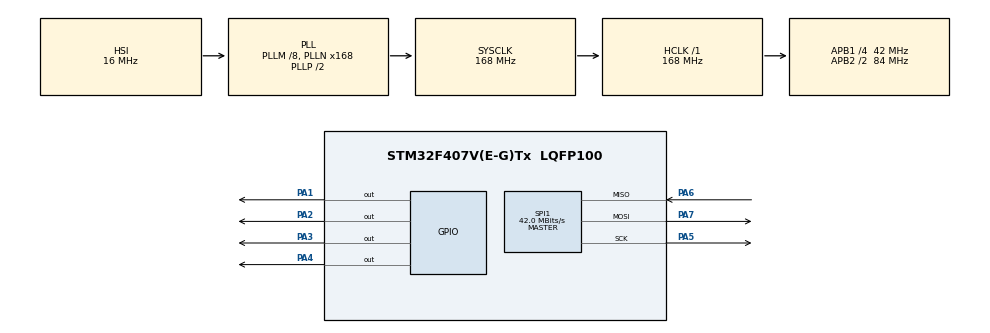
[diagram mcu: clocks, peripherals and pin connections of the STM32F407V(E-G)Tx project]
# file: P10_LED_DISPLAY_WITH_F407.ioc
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Mcu.Family=STM32F4
Mcu.Name=STM32F407V(E-G)Tx
Mcu.Package=LQFP100
NVIC.PriorityGroup=NVIC_PRIORITYGROUP_0
PA1.Signal=GPIO_Output
PA2.Signal=GPIO_Output
PA3.Signal=GPIO_Output
PA4.Signal=GPIO_Output
PA5.Mode=Full_Duplex_Master
PA5.Signal=SPI1_SCK
PA6.Mode=Full_Duplex_Master
PA6.Signal=SPI1_MISO
PA7.Mode=Full_Duplex_Master
PA7.Signal=SPI1_MOSI
ProjectManager.HeapSize=0x200
ProjectManager.StackSize=0x400
ProjectManager.TargetToolchain=STM32CubeIDE
RCC.48MHZClocksFreq_Value=48000000
RCC.AHBFreq_Value=168000000
RCC.APB1CLKDivider=RCC_HCLK_DIV4
RCC.APB1Freq_Value=42000000
RCC.APB1TimFreq_Value=84000000
RCC.APB2CLKDivider=RCC_HCLK_DIV2
RCC.APB2Freq_Value=84000000
RCC.APB2TimFreq_Value=168000000
RCC.CortexFreq_Value=168000000
RCC.HCLKFreq_Value=168000000
RCC.HSE_VALUE=8000000
RCC.HSI_VALUE=16000000
RCC.LSE_VALUE=32768
RCC.PLLM=8
RCC.PLLN=168
RCC.PLLQ=7
RCC.SYSCLKFreq_VALUE=168000000
RCC.SYSCLKSource=RCC_SYSCLKSOURCE_PLLCLK
RCC.VCOOutputFreq_Value=336000000
SPI1.CalculateBaudRate=42.0 MBits/s
SPI1.Direction=SPI_DIRECTION_2LINES
SPI1.Mode=SPI_MODE_MASTER
SPI1.VirtualType=VM_MASTER
TIM2.Period=10000
TIM2.Prescaler=8400
VP_TIM2_VS_ClockSourceINT.Mode=Internal
board=STM32F407G-DISC1

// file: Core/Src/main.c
/* USER CODE BEGIN Header */
/**
  ******************************************************************************
  * @file           : main.c
  * @brief          : Main program body
  ******************************************************************************
  * @attention
  *
  * Copyright (c) 2023 STMicroelectronics.
  * All rights reserved.
  *
  * This software is licensed under terms that can be found in the LICENSE file
  * in the root directory of this software component.
  * If no LICENSE file comes with this software, it is provided AS-IS.
  *
  ******************************************************************************
  */
/* USER CODE END Header */
#include "main.h"
#include"DMD.h"
#include"Arial14.h"
#include "Arial_Black_16_ISO_8859_1.h"
#include "Arial_black_16.h"
#include "SystemFont5x7.h"

SPI_HandleTypeDef hspi1;

TIM_HandleTypeDef htim2;

void SystemClock_Config(void);
static void MX_GPIO_Init(void);
static void MX_SPI1_Init(void);
static void MX_TIM2_Init(void);
/* USER CODE BEGIN PFP */
void DMD_scanDisplayBySPI(DMD *dmd);
/* USER CODE END PFP */

DMD *dmd;
/*** @brief  The application entry point.
  * @retval int
  */
int main(void)
{

  /* MCU Configuration--------------------------------------------------------*/

  /* Reset of all peripherals, Initializes the Flash interface and the Systick. */
  HAL_Init();

  /* Configure the system clock */
  SystemClock_Config();

  /* Initialize all configured peripherals */
  MX_GPIO_Init();
  MX_SPI1_Init();
  MX_TIM2_Init();
  /* USER CODE BEGIN 2 */
//dmd.=(1,1);

DMD_init(dmd,1,1);
  // Initialize the DMD display
//  DMD_begin(dmd);

  // Set the font for the DMD instance (replace MyFont with your font)
  DMD_selectFont(dmd,Arial_Black_16_ISO_8859_1);

  // Define the position (X, Y) where you want to draw the string
  int bX = 0;
  int bY = 0;

  // Define the string you want to display
  const char *bChars = "AAAA";

  // Get the length of the string
  uint8_t length = strlen(bChars);

  // Set the graphics mode (GRAPHICS_NORMAL, GRAPHICS_INVERSE, etc.)
  uint8_t bGraphicsMode = GRAPHICS_NORMAL;
  HAL_TIM_Base_Start_IT(&htim2);
  /* Infinite loop */
  while (1)
  {

	      // Call DMD_drawString to draw the string on the DMD display
	      DMD_drawString(dmd, bX, bY, bChars, length, bGraphicsMode);

	      // You may need to update the display and add a delay to keep the message visible

	      // Delay for 1 second to display the message
	      // You can adjust the delay duration as needed
	      HAL_Delay(1000);
	  	DMD_scanDisplayBySPI(dmd);

	      // Don't forget to free the DMD instance when done

	      return 0; /* USER CODE END 2 */

  }
}

void SystemClock_Config(void)
{
  RCC_OscInitTypeDef RCC_OscInitStruct = {0};
  RCC_ClkInitTypeDef RCC_ClkInitStruct = {0};

  /** Configure the main internal regulator output voltage
  */
  __HAL_RCC_PWR_CLK_ENABLE();
  __HAL_PWR_VOLTAGESCALING_CONFIG(PWR_REGULATOR_VOLTAGE_SCALE1);

  /** Initializes the RCC Oscillators according to the specified parameters
  * in the RCC_OscInitTypeDef structure.
  */
  RCC_OscInitStruct.OscillatorType = RCC_OSCILLATORTYPE_HSI;
  RCC_OscInitStruct.HSIState = RCC_HSI_ON;
  RCC_OscInitStruct.HSICalibrationValue = RCC_HSICALIBRATION_DEFAULT;
  RCC_OscInitStruct.PLL.PLLState = RCC_PLL_ON;
  RCC_OscInitStruct.PLL.PLLSource = RCC_PLLSOURCE_HSI;
  RCC_OscInitStruct.PLL.PLLM = 8;
  RCC_OscInitStruct.PLL.PLLN = 168;
  RCC_OscInitStruct.PLL.PLLP = RCC_PLLP_DIV2;
  RCC_OscInitStruct.PLL.PLLQ = 7;
  if (HAL_RCC_OscConfig(&RCC_OscInitStruct) != HAL_OK)
  {
    Error_Handler();
  }

  /** Initializes the CPU, AHB and APB buses clocks
  */
  RCC_ClkInitStruct.ClockType = RCC_CLOCKTYPE_HCLK|RCC_CLOCKTYPE_SYSCLK
                              |RCC_CLOCKTYPE_PCLK1|RCC_CLOCKTYPE_PCLK2;
  RCC_ClkInitStruct.SYSCLKSource = RCC_SYSCLKSOURCE_PLLCLK;
  RCC_ClkInitStruct.AHBCLKDivider = RCC_SYSCLK_DIV1;
  RCC_ClkInitStruct.APB1CLKDivider = RCC_HCLK_DIV4;
  RCC_ClkInitStruct.APB2CLKDivider = RCC_HCLK_DIV2;

  if (HAL_RCC_ClockConfig(&RCC_ClkInitStruct, FLASH_LATENCY_5) != HAL_OK)
  {
    Error_Handler();
  }
}

static void MX_SPI1_Init(void)
{

  /* SPI1 parameter configuration*/
  hspi1.Instance = SPI1;
  hspi1.Init.Mode = SPI_MODE_MASTER;
  hspi1.Init.Direction = SPI_DIRECTION_2LINES;
  hspi1.Init.DataSize = SPI_DATASIZE_8BIT;
  hspi1.Init.CLKPolarity = SPI_POLARITY_LOW;
  hspi1.Init.CLKPhase = SPI_PHASE_1EDGE;
  hspi1.Init.NSS = SPI_NSS_SOFT;
  hspi1.Init.BaudRatePrescaler = SPI_BAUDRATEPRESCALER_2;
  hspi1.Init.FirstBit = SPI_FIRSTBIT_MSB;
  hspi1.Init.TIMode = SPI_TIMODE_DISABLE;
  hspi1.Init.CRCCalculation = SPI_CRCCALCULATION_DISABLE;
  hspi1.Init.CRCPolynomial = 10;
  if (HAL_SPI_Init(&hspi1) != HAL_OK)
  {
    Error_Handler();
  }

}

static void MX_TIM2_Init(void)
{

  TIM_ClockConfigTypeDef sClockSourceConfig = {0};
  TIM_MasterConfigTypeDef sMasterConfig = {0};

  htim2.Instance = TIM2;
  htim2.Init.Prescaler = 8400;
  htim2.Init.CounterMode = TIM_COUNTERMODE_UP;
  htim2.Init.Period = 10000;
  htim2.Init.ClockDivision = TIM_CLOCKDIVISION_DIV1;
  htim2.Init.AutoReloadPreload = TIM_AUTORELOAD_PRELOAD_DISABLE;
  if (HAL_TIM_Base_Init(&htim2) != HAL_OK)
  {
    Error_Handler();
  }
  sClockSourceConfig.ClockSource = TIM_CLOCKSOURCE_INTERNAL;
  if (HAL_TIM_ConfigClockSource(&htim2, &sClockSourceConfig) != HAL_OK)
  {
    Error_Handler();
  }
  sMasterConfig.MasterOutputTrigger = TIM_TRGO_RESET;
  sMasterConfig.MasterSlaveMode = TIM_MASTERSLAVEMODE_DISABLE;
  if (HAL_TIMEx_MasterConfigSynchronization(&htim2, &sMasterConfig) != HAL_OK)
  {
    Error_Handler();
  }

}
void HAL_TIM_PeriodElapsedCallback(TIM_HandleTypeDef *htim)
{

}
static void MX_GPIO_Init(void)
{
  GPIO_InitTypeDef GPIO_InitStruct = {0};

  /* GPIO Ports Clock Enable */
  __HAL_RCC_GPIOA_CLK_ENABLE();

  /*Configure GPIO pin Output Level */
  HAL_GPIO_WritePin(GPIOA, GPIO_PIN_1|GPIO_PIN_2|GPIO_PIN_3|GPIO_PIN_4, GPIO_PIN_RESET);

  /*Configure GPIO pins : PA1 PA2 PA3 PA4 */
  GPIO_InitStruct.Pin = GPIO_PIN_1|GPIO_PIN_2|GPIO_PIN_3|GPIO_PIN_4;
  GPIO_InitStruct.Mode = GPIO_MODE_OUTPUT_PP;
  GPIO_InitStruct.Pull = GPIO_NOPULL;
  GPIO_InitStruct.Speed = GPIO_SPEED_FREQ_LOW;
  HAL_GPIO_Init(GPIOA, &GPIO_InitStruct);

}

void Error_Handler(void)
{
  __disable_irq();
  while (1)
  {
  }
}
